# STM32F100 register map
File version: 1.1
CPU: CM3 r1p1, little endian, no MPU, no FPU, 4 interrupt priority bits
Registers are 32-bit, read-write, reset 0x0 unless marked. A register's access mark holds for its fields unless they carry their own. Offsets are from the block's base; [hi:lo] are bit positions; {n}, {i} and the like mark numbered series.

## BKP — Backup registers
Base 0x40006C04
0x00 DR{i} (i=1..10; step 0x4) — Backup data register (BKP_DR)
  [15:0] D — Backup data
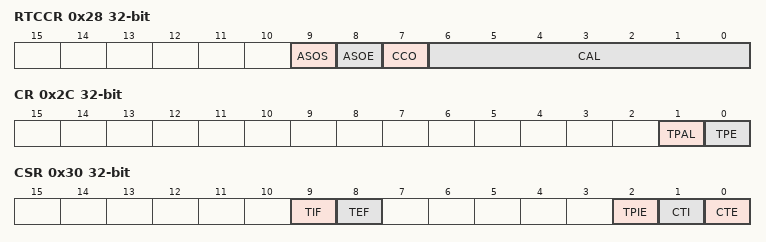
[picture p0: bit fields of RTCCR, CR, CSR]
0x28 RTCCR — RTC clock calibration register (BKP_RTCCR)
  [9] ASOS — Alarm or second output selection
    0=Alarm (RTC Alarm pulse output selected); 1=Second (RTC Second pulse output selected)
  [8] ASOE — Alarm or second output enable
    0=Disabled; 1=Enabled (Setting this bit outputs either the RTC Alarm pulse signal or the Second pulse signal on the TAMPER pin depending on the ASOS bit)
  [7] CCO — Calibration Clock Output
  [6:0] CAL range 0..121 — Calibration value
0x2C CR — Backup control register (BKP_CR)
  [1] TPAL — Tamper pin active level
    0=High (A high level on the TAMPER pin resets all data backup registers (if TPE bit is set)); 1=Low (A low level on the TAMPER pin resets all data backup registers (if TPE bit is set))
  [0] TPE — Tamper pin enable
    0=General (The TAMPER pin is free for general purpose I/O); 1=Alternate (Tamper alternate I/O function is activated)
0x30 CSR access per field — BKP_CSR control/status register (BKP_CSR)
  [9] TIF ro — Tamper Interrupt Flag
  [8] TEF ro — Tamper Event Flag
  [2] TPIE rw — Tamper Pin interrupt enable
    0=Disabled (Tamper interrupt disabled); 1=Enabled (Tamper interrupt enabled (the TPE bit must also be set in the BKP_CR register)
  [1] CTI wo — Clear Tamper Interrupt
    1=Clear the Tamper interrupt and the TIF Tamper interrupt flag
  [0] CTE wo — Clear Tamper event
    1=Reset the TEF Tamper event flag (and the Tamper detector)
{0x10+4i} BKP_DR{i} (i=11..42) — Backup data register (BKP_DR)
  [15:0] D — Backup data

## IWDG — Independent watchdog
Base 0x40003000
0x00 KR 16-bit wo — Key register (IWDG_KR)
  [15:0] KEY — Key value
    0x5555=Unlock (Enable access to PR, RLR and WINR registers); 0xAAAA=Feed watchdog with RLR register value; 0xCCCC=Start the watchdog
0x04 PR 16-bit — Prescaler register (IWDG_PR)
  [2:0] PR — Prescaler divider
    0=DivideBy4 (Divider /4); 1=DivideBy8 (Divider /8); 2=DivideBy16 (Divider /16); 3=DivideBy32 (Divider /32); 4=DivideBy64 (Divider /64); 5=DivideBy128 (Divider /128); other=DivideBy256 (Divider /256)
0x08 RLR 16-bit reset 0xFFF — Reload register (IWDG_RLR)
  [11:0] RL — Watchdog counter reload value
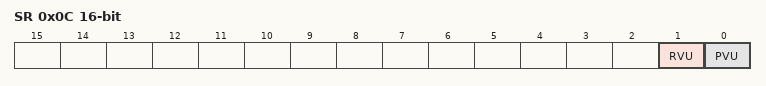
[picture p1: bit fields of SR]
0x0C SR 16-bit ro — Status register (IWDG_SR)
  [1] RVU — Watchdog counter reload value update
  [0] PVU — Watchdog prescaler value update

## WWDG — Window watchdog
Base 0x40002C00
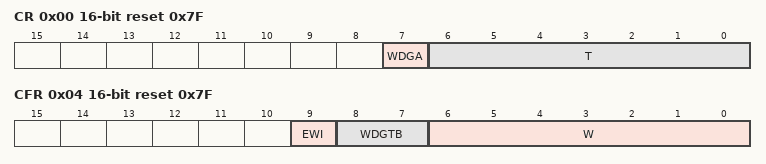
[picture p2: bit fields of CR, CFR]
0x00 CR 16-bit reset 0x7F — Control register (WWDG_CR)
  [7] WDGA — Activation bit
    0=Disabled (Watchdog disabled); 1=Enabled (Watchdog enabled)
  [6:0] T — 7-bit counter (MSB to LSB)
0x04 CFR 16-bit reset 0x7F — Configuration register (WWDG_CFR)
  [9] EWI — Early Wakeup Interrupt
    on write: 1=Enable (interrupt occurs whenever the counter reaches the value 0x40)
  [8:7] WDGTB — Timer Base
    0=Div1 (Counter clock (PCLK1 div 4096) div 1); 1=Div2 (Counter clock (PCLK1 div 4096) div 2); 2=Div4 (Counter clock (PCLK1 div 4096) div 4); 3=Div8 (Counter clock (PCLK1 div 4096) div 8)
  [6:0] W — 7-bit window value
0x08 SR 16-bit — Status register (WWDG_SR)
  [0] EWIF write-0-clears — Early Wakeup Interrupt
    on read: 0=Finished (The EWI Interrupt Service Routine has been serviced); 1=Pending (The EWI Interrupt Service Routine has been triggered) | on write: 0=Finished (The EWI Interrupt Service Routine has been serviced)

## TIM6 — Basic timer
Base 0x40001000
Same registers: TIM7 0x40001400
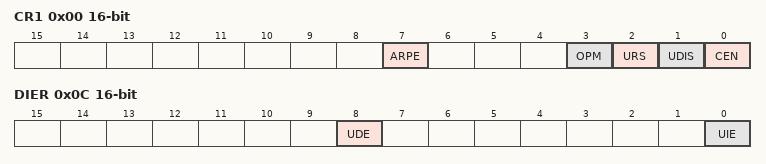
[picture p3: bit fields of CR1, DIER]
0x00 CR1 16-bit — control register 1
  [7] ARPE — Auto-reload preload enable
    0=Disabled (TIMx_APRR register is not buffered); 1=Enabled (TIMx_APRR register is buffered)
  [3] OPM — One-pulse mode
    0=Disabled (Counter is not stopped at update event); 1=Enabled (Counter stops counting at the next update event (clearing the CEN bit))
  [2] URS — Update request source
    0=AnyEvent (Any of counter overflow/underflow, setting UG, or update through slave mode, generates an update interrupt or DMA request); 1=CounterOnly (Only counter overflow/underflow generates an update interrupt or DMA request)
  [1] UDIS — Update disable
    0=Enabled (Update event enabled); 1=Disabled (Update event disabled)
  [0] CEN — Counter enable
    0=Disabled (Counter disabled); 1=Enabled (Counter enabled)
0x04 CR2 16-bit — control register 2
  [6:4] MMS — Master mode selection
    0=Reset (Use UG bit from TIMx_EGR register); 1=Enable (Use CNT bit from TIMx_CEN register); 2=Update (Use the update event)
0x0C DIER 16-bit — DMA/Interrupt enable register
  [8] UDE — Update DMA request enable
    0=Disabled (Update DMA request disabled); 1=Enabled (Update DMA request enabled)
  [0] UIE — Update interrupt enable
    0=Disabled (Update interrupt disabled); 1=Enabled (Update interrupt enabled)
0x10 SR 16-bit — status register
  [0] UIF write-0-clears — Update interrupt flag
    on read: 0=NoUpdateOccurred; 1=UpdatePending (Update interrupt pending) | on write: 0=Clear flag
0x14 EGR 16-bit wo — event generation register
  [0] UG — Update generation
    1=Update (Re-initializes the timer counter and generates an update of the registers.)
0x24 CNT 16-bit — counter
  [15:0] CNT — Low counter value
0x28 PSC 16-bit — prescaler
  [15:0] PSC — Prescaler value
0x2C ARR 16-bit — auto-reload register
  [15:0] ARR — Low Auto-reload value
